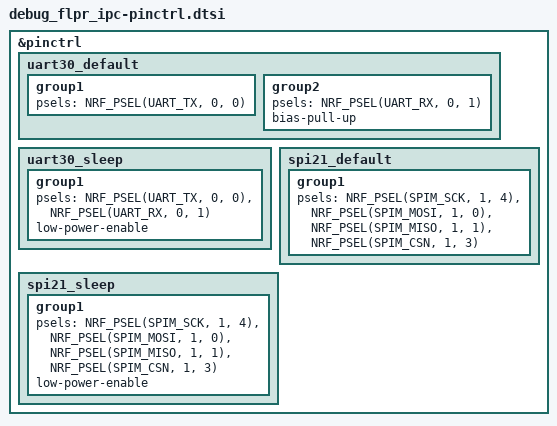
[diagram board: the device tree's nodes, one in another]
&pinctrl {
	uart30_default: uart30_default {
		group1 {
			psels = <NRF_PSEL(UART_TX, 0, 0)>;
		};

		group2 {
			psels = <NRF_PSEL(UART_RX, 0, 1)>;
			bias-pull-up;
		};
	};

	uart30_sleep: uart30_sleep {
		group1 {
			psels = <NRF_PSEL(UART_TX, 0, 0)>,
				<NRF_PSEL(UART_RX, 0, 1)>;
			low-power-enable;
		};
	};

	spi21_default: spi21_default {
		group1 {
			psels = <NRF_PSEL(SPIM_SCK, 1, 4)>,
				<NRF_PSEL(SPIM_MOSI, 1, 0)>,
				<NRF_PSEL(SPIM_MISO, 1, 1)>,
				<NRF_PSEL(SPIM_CSN, 1, 3)>;
		};
	};

	spi21_sleep: spi21_sleep {
		group1 {
			psels = <NRF_PSEL(SPIM_SCK, 1, 4)>,
				<NRF_PSEL(SPIM_MOSI, 1, 0)>,
				<NRF_PSEL(SPIM_MISO, 1, 1)>,
				<NRF_PSEL(SPIM_CSN, 1, 3)>;
			low-power-enable;
		};
	};
};
